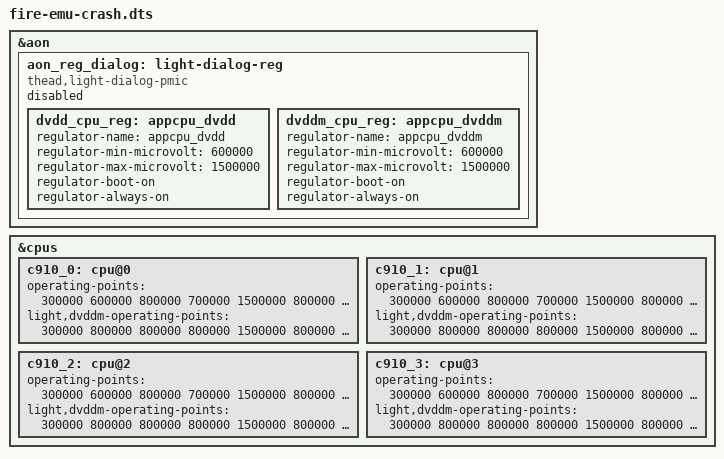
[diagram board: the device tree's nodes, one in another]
/* SPDX-License-Identifier: GPL-2.0 */
/*
 * Copyright (C) 2021 Alibaba Group Holding Limited.
 */

#include "fire-crash.dts"

&aon {
	aon_reg_dialog: light-dialog-reg {
		compatible = "thead,light-dialog-pmic";
		status = "disabled";

		dvdd_cpu_reg: appcpu_dvdd {
			regulator-name = "appcpu_dvdd";
			regulator-min-microvolt = <600000>;
			regulator-max-microvolt = <1500000>;
			regulator-boot-on;
			regulator-always-on;
		};

		dvddm_cpu_reg: appcpu_dvddm {
			regulator-name = "appcpu_dvddm";
			regulator-min-microvolt = <600000>;
			regulator-max-microvolt = <1500000>;
			regulator-boot-on;
			regulator-always-on;
		};
	};
};

&cpus {
	c910_0: cpu@0 {
		operating-points = <
			/* kHz    uV */
			300000	600000
			800000	700000
			1500000	800000
			1848000 1000000
		>;
		light,dvddm-operating-points = <
			/* kHz   uV */
			300000	800000
			800000	800000
			1500000	800000
			1848000 1000000
		>;
	};
	c910_1: cpu@1 {
		operating-points = <
			/* kHz    uV */
			300000	600000
			800000	700000
			1500000	800000
			1848000 1000000
		>;
		light,dvddm-operating-points = <
			/* kHz   uV */
			300000	800000
			800000	800000
			1500000	800000
			1848000 1000000
		>;
	};
	c910_2: cpu@2 {

		operating-points = <
			/* kHz    uV */
			300000	600000
			800000	700000
			1500000	800000
			1848000 1000000
		>;
		light,dvddm-operating-points = <
			/* kHz   uV */
			300000	800000
			800000	800000
			1500000	800000
			1848000 1000000
		>;
	};
	c910_3: cpu@3 {

		operating-points = <
			/* kHz    uV */
			300000	600000
			800000	700000
			1500000	800000
			1848000 1000000
		>;
		light,dvddm-operating-points = <
			/* kHz   uV */
			300000	800000
			800000	800000
			1500000	800000
			1848000 1000000
		>;
	};
};
